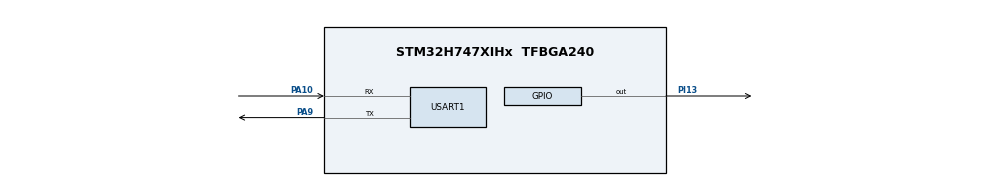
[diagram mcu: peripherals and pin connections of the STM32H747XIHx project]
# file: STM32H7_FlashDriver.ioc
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CORTEX_M7.default_mode_Activation=1
CortexM4.IPs=BDMA,CORTEX_M4\:I,DMA,FATFS_M4\:I,FREERTOS_M4\:I,GPIO,IWDG2\:I,MDMA,NVIC2\:I,OPENAMP_M4\:I,PDM2PCM_M4\:I,PWR,RCC,RESMGR_UTILITY,SYS_M4\:I,USB_DEVICE_M4\:I,USB_HOST_M4\:I,VREFBUF,WWDG2\:I
CortexM7.IPs=BDMA\:I,CORTEX_M7\:I,DMA\:I,FATFS_M7\:I,FREERTOS_M7\:I,GPIO\:I,IWDG1\:I,MDMA\:I,NVIC1\:I,OPENAMP_M7\:I,PDM2PCM_M7\:I,PWR\:I,RCC\:I,RESMGR_UTILITY\:I,SYS\:I,USB_DEVICE_M7\:I,USB_HOST_M7\:I,VREFBUF\:I,WWDG1\:I,MEMORYMAP\:I,USART1\:I
Dma.Request0=USART1_TX
Dma.USART1_TX.0.Direction=DMA_MEMORY_TO_PERIPH
Dma.USART1_TX.0.EventEnable=DISABLE
Dma.USART1_TX.0.FIFOMode=DMA_FIFOMODE_DISABLE
Dma.USART1_TX.0.Instance=DMA1_Stream0
Dma.USART1_TX.0.MemDataAlignment=DMA_MDATAALIGN_BYTE
Dma.USART1_TX.0.MemInc=DMA_MINC_ENABLE
Dma.USART1_TX.0.Mode=DMA_NORMAL
Dma.USART1_TX.0.PeriphDataAlignment=DMA_PDATAALIGN_BYTE
Dma.USART1_TX.0.PeriphInc=DMA_PINC_DISABLE
Dma.USART1_TX.0.Polarity=HAL_DMAMUX_REQ_GEN_RISING
Dma.USART1_TX.0.Priority=DMA_PRIORITY_LOW
Dma.USART1_TX.0.RequestNumber=1
Dma.USART1_TX.0.SignalID=NONE
Dma.USART1_TX.0.SyncEnable=DISABLE
Dma.USART1_TX.0.SyncPolarity=HAL_DMAMUX_SYNC_NO_EVENT
Dma.USART1_TX.0.SyncRequestNumber=1
Dma.USART1_TX.0.SyncSignalID=NONE
Mcu.Family=STM32H7
Mcu.Name=STM32H747XIHx
Mcu.Package=TFBGA240
NVIC1.DMA1_Stream0_IRQn=true\:0\:0\:false\:false\:true\:false\:true\:true
NVIC1.FLASH_IRQn=true\:0\:0\:false\:false\:true\:true\:true\:true
NVIC1.PriorityGroup=NVIC_PRIORITYGROUP_4
NVIC1.USART1_IRQn=true\:0\:0\:false\:false\:true\:true\:true\:true
NVIC2.PriorityGroup=NVIC_PRIORITYGROUP_4
PA10.Mode=Asynchronous
PA10.PinAttribute=CortexM7
PA10.Signal=USART1_RX
PA9.Mode=Asynchronous
PA9.PinAttribute=CortexM7
PA9.Signal=USART1_TX
PB3\ (JTDO/TRACESWO).Signal=DEBUG_JTDO-SWO
PI13.PinAttribute=Free
PI13.Signal=GPIO_Output
ProjectManager.HeapSize=M4-0x200,M7-0x200
ProjectManager.StackSize=M4-0x400,M7-0x400
ProjectManager.TargetToolchain=STM32CubeIDE
RCC.ADCFreq_Value=129000000
RCC.APB1Freq_Value=64000000
RCC.APB2Freq_Value=32000000
RCC.APB3Freq_Value=64000000
RCC.APB4Freq_Value=64000000
RCC.CortexFreq_Value=64000000
RCC.D2PPRE2=RCC_APB2_DIV2
RCC.HCLKFreq_Value=64000000
RCC.SYSCLKFreq_VALUE=64000000
RCC.USBFreq_Value=129000000
SYS.userName=SYS_M7
USART1.VirtualMode-Asynchronous=VM_ASYNC
VP_MEMORYMAP_VS_MEMORYMAP.Mode=CurAppReg
VP_SYS_M4_VS_Systick.Mode=SysTick
board=custom

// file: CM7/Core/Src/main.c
/* USER CODE BEGIN Header */
/**
  ******************************************************************************
  * @file           : main.c
  * @brief          : Main program body
  ******************************************************************************
  * @attention
  *
  * Copyright (c) 2026 STMicroelectronics.
  * All rights reserved.
  *
  * This software is licensed under terms that can be found in the LICENSE file
  * in the root directory of this software component.
  * If no LICENSE file comes with this software, it is provided AS-IS.
  *
  ******************************************************************************
  */
/* USER CODE END Header */
#include "main.h"

/* USER CODE BEGIN Includes */

#include "app_main.h"

/* USER CODE END Includes */

/* USER CODE BEGIN PD */

#ifndef HSEM_ID_0
#define HSEM_ID_0 (0U) /* HW semaphore 0*/
#endif

/* USER CODE END PD */

UART_HandleTypeDef huart1;
DMA_HandleTypeDef hdma_usart1_tx;

void SystemClock_Config(void);
static void MPU_Config(void);
static void MX_GPIO_Init(void);
static void MX_DMA_Init(void);
static void MX_USART1_UART_Init(void);

int main(void)
{

  /* USER CODE BEGIN 1 */

	SCB->VTOR = FLASH_BANK1_BASE;

  /* USER CODE END 1 */
/* USER CODE BEGIN Boot_Mode_Sequence_0 */
  int32_t timeout;
/* USER CODE END Boot_Mode_Sequence_0 */

  /* MPU Configuration--------------------------------------------------------*/
//  MPU_Config();

/* USER CODE BEGIN Boot_Mode_Sequence_1 */
  /* Wait until CPU2 boots and enters in stop mode or timeout*/
  timeout = 0xFFFF;
 /*
  while((__HAL_RCC_GET_FLAG(RCC_FLAG_D2CKRDY) != RESET) && (timeout-- > 0));
  if ( timeout < 0 )
  {
	//  Error_Handler();
  }
  */
/* USER CODE END Boot_Mode_Sequence_1 */
  /* MCU Configuration--------------------------------------------------------*/

  /* Reset of all peripherals, Initializes the Flash interface and the Systick. */
  HAL_Init();

  /* Configure the system clock */
  SystemClock_Config();
/* USER CODE BEGIN Boot_Mode_Sequence_2 */
/* When system initialization is finished, Cortex-M7 will release Cortex-M4 by means of
HSEM notification */
/*HW semaphore Clock enable*/
__HAL_RCC_HSEM_CLK_ENABLE();
/*Take HSEM */
HAL_HSEM_FastTake(HSEM_ID_0);
/*Release HSEM in order to notify the CPU2(CM4)*/
HAL_HSEM_Release(HSEM_ID_0,0);
/* wait until CPU2 wakes up from stop mode */
timeout = 0xFFFF;
while((__HAL_RCC_GET_FLAG(RCC_FLAG_D2CKRDY) == RESET) && (timeout-- > 0));
if ( timeout < 0 )
{
//Error_Handler();
}
/* USER CODE END Boot_Mode_Sequence_2 */

  /* Initialize all configured peripherals */
  MX_GPIO_Init();
  MX_DMA_Init();
  MX_USART1_UART_Init();
  /* USER CODE BEGIN 2 */

	HAL_NVIC_SetPriority(FLASH_IRQn, 5, 0);
	HAL_NVIC_EnableIRQ(FLASH_IRQn);

	app_init();

	HAL_NVIC_SetPriority(USART1_IRQn, 5, 0);
	HAL_NVIC_EnableIRQ(USART1_IRQn);

  /* USER CODE END 2 */

  /* Infinite loop */
  while (1)
  {

    /* USER CODE BEGIN 3 */

	app_loop();
  }
  /* USER CODE END 3 */
}

void SystemClock_Config(void)
{
  RCC_OscInitTypeDef RCC_OscInitStruct = {0};
  RCC_ClkInitTypeDef RCC_ClkInitStruct = {0};

  /** Supply configuration update enable
  */
  HAL_PWREx_ConfigSupply(PWR_DIRECT_SMPS_SUPPLY);

  /** Configure the main internal regulator output voltage
  */
  __HAL_PWR_VOLTAGESCALING_CONFIG(PWR_REGULATOR_VOLTAGE_SCALE3);

  while(!__HAL_PWR_GET_FLAG(PWR_FLAG_VOSRDY)) {}

  /** Initializes the RCC Oscillators according to the specified parameters
  * in the RCC_OscInitTypeDef structure.
  */
  RCC_OscInitStruct.OscillatorType = RCC_OSCILLATORTYPE_HSI;
  RCC_OscInitStruct.HSIState = RCC_HSI_DIV1;
  RCC_OscInitStruct.HSICalibrationValue = RCC_HSICALIBRATION_DEFAULT;
  RCC_OscInitStruct.PLL.PLLState = RCC_PLL_NONE;
  if (HAL_RCC_OscConfig(&RCC_OscInitStruct) != HAL_OK)
  {
    Error_Handler();
  }

  /** Initializes the CPU, AHB and APB buses clocks
  */
  RCC_ClkInitStruct.ClockType = RCC_CLOCKTYPE_HCLK|RCC_CLOCKTYPE_SYSCLK
                              |RCC_CLOCKTYPE_PCLK1|RCC_CLOCKTYPE_PCLK2
                              |RCC_CLOCKTYPE_D3PCLK1|RCC_CLOCKTYPE_D1PCLK1;
  RCC_ClkInitStruct.SYSCLKSource = RCC_SYSCLKSOURCE_HSI;
  RCC_ClkInitStruct.SYSCLKDivider = RCC_SYSCLK_DIV1;
  RCC_ClkInitStruct.AHBCLKDivider = RCC_HCLK_DIV1;
  RCC_ClkInitStruct.APB3CLKDivider = RCC_APB3_DIV1;
  RCC_ClkInitStruct.APB1CLKDivider = RCC_APB1_DIV1;
  RCC_ClkInitStruct.APB2CLKDivider = RCC_APB2_DIV2;
  RCC_ClkInitStruct.APB4CLKDivider = RCC_APB4_DIV1;

  if (HAL_RCC_ClockConfig(&RCC_ClkInitStruct, FLASH_LATENCY_1) != HAL_OK)
  {
    Error_Handler();
  }
}

static void MX_USART1_UART_Init(void)
{

  huart1.Instance = USART1;
  huart1.Init.BaudRate = 115200;
  huart1.Init.WordLength = UART_WORDLENGTH_8B;
  huart1.Init.StopBits = UART_STOPBITS_1;
  huart1.Init.Parity = UART_PARITY_NONE;
  huart1.Init.Mode = UART_MODE_TX_RX;
  huart1.Init.HwFlowCtl = UART_HWCONTROL_NONE;
  huart1.Init.OverSampling = UART_OVERSAMPLING_16;
  huart1.Init.OneBitSampling = UART_ONE_BIT_SAMPLE_DISABLE;
  huart1.Init.ClockPrescaler = UART_PRESCALER_DIV1;
  huart1.AdvancedInit.AdvFeatureInit = UART_ADVFEATURE_NO_INIT;
  if (HAL_UART_Init(&huart1) != HAL_OK)
  {
    Error_Handler();
  }
  if (HAL_UARTEx_SetTxFifoThreshold(&huart1, UART_TXFIFO_THRESHOLD_1_8) != HAL_OK)
  {
    Error_Handler();
  }
  if (HAL_UARTEx_SetRxFifoThreshold(&huart1, UART_RXFIFO_THRESHOLD_1_8) != HAL_OK)
  {
    Error_Handler();
  }
  if (HAL_UARTEx_DisableFifoMode(&huart1) != HAL_OK)
  {
    Error_Handler();
  }

}

static void MX_DMA_Init(void)
{

  /* DMA controller clock enable */
  __HAL_RCC_DMA1_CLK_ENABLE();

  /* DMA interrupt init */
  /* DMA1_Stream0_IRQn interrupt configuration */
  HAL_NVIC_SetPriority(DMA1_Stream0_IRQn, 0, 0);
  HAL_NVIC_EnableIRQ(DMA1_Stream0_IRQn);

}

static void MX_GPIO_Init(void)
{

  /* GPIO Ports Clock Enable */
  __HAL_RCC_GPIOA_CLK_ENABLE();

}

 /* MPU Configuration */

void MPU_Config(void)
{
  MPU_Region_InitTypeDef MPU_InitStruct = {0};

  /* Disables the MPU */
  HAL_MPU_Disable();

  /** Initializes and configures the Region and the memory to be protected
  */
  MPU_InitStruct.Enable = MPU_REGION_ENABLE;
  MPU_InitStruct.Number = MPU_REGION_NUMBER0;
  MPU_InitStruct.BaseAddress = 0x0;
  MPU_InitStruct.Size = MPU_REGION_SIZE_4GB;
  MPU_InitStruct.SubRegionDisable = 0x87;
  MPU_InitStruct.TypeExtField = MPU_TEX_LEVEL0;
  MPU_InitStruct.AccessPermission = MPU_REGION_NO_ACCESS;
  MPU_InitStruct.DisableExec = MPU_INSTRUCTION_ACCESS_DISABLE;
  MPU_InitStruct.IsShareable = MPU_ACCESS_SHAREABLE;
  MPU_InitStruct.IsCacheable = MPU_ACCESS_NOT_CACHEABLE;
  MPU_InitStruct.IsBufferable = MPU_ACCESS_NOT_BUFFERABLE;

  HAL_MPU_ConfigRegion(&MPU_InitStruct);
  /* Enables the MPU */
  HAL_MPU_Enable(MPU_PRIVILEGED_DEFAULT);

}

void Error_Handler(void)
{
  __disable_irq();
  while (1)
  {
  }
}
